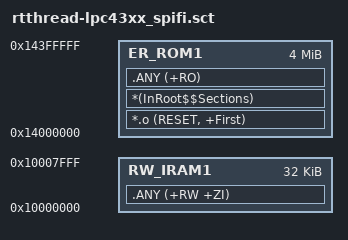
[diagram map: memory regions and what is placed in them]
; *************************************************************
; *** Scatter-Loading Description File generated by uVision ***
; *************************************************************

LR_ROM1 0x14000000 0x00400000  {    ; load region size_region
  ER_ROM1 0x14000000 0x00400000  {  ; load address = execution address
   *.o (RESET, +First)
   *(InRoot$$Sections)
   .ANY (+RO)
  }
  RW_IRAM1 0x10000000 0x00008000  {  ; RW data
   .ANY (+RW +ZI)
  }
}

